VERSION "HIPBNYYYYYYYYYYYYYYYYYYYYYYYYYYYYYYYYYYYYY/4/%%%/4/'%**4YYY///"

NS_ :

BS_:

BU_: VCU DCDC

BO_ 2566834864 DcDc_DM1: 6 DCDC

BO_ 2565406640 DcDc_unknown: 8 DCDC

BO_ 2632712112 DcDc_TPDT: 8 DCDC

BO_ 2632777648 DcDc_TPCM: 8 DCDC

BO_ 2565518331 DcDc_RQST: 8 DCDC
 SG_ ParameterGroupNumber : 0|24@1+ (1,0) [0|0] "" Vector__XXX

BO_ 2565845243 VCU_DcDc_Setpoints: 8 VCU
 SG_ CMD_RemoteTurnOn m0 : 40|1@1+ (1,0) [0|1] ""  DCDC
 SG_ CMD_CoolantTempWarning_Threshold m2 : 24|16@1- (0.1,0) [40|90] "deg C"  DCDC
 SG_ CMD_CoolantTempFault_Threshold m2 : 8|16@1- (0.1,0) [50|90] "deg C"  DCDC
 SG_ CMD_OutputUnderVoltageFaultThres m1 : 8|16@1+ (0.05,0) [8|15.95] "V"  DCDC
 SG_ CMD_OutputOverVoltageFaultThresh m1 : 24|16@1+ (0.05,0) [9.05|18] "V"  DCDC
 SG_ CMD_OutputCurrentLimit m0 : 24|16@1+ (0.05,0) [200|291] "A"  DCDC
 SG_ CMD_OutputVoltageSetpoint m0 : 8|16@1+ (0.05,0) [9|16] "V"  DCDC
 SG_ index_byte M : 0|8@1+ (1,0) [0|255] ""  DCDC

BO_ 2566902960 DcDc_F_W_S_Message: 8 DCDC
 SG_ STS_Hiccup : 57|1@1+ (1,0) [0|1] ""  VCU
 SG_ STS_ReversPolarity : 56|1@1+ (1,0) [0|1] ""  VCU
 SG_ FLT_ReversPolarity : 13|1@1+ (1,0) [0|1] ""  VCU
 SG_ WAR_CurrentLimiting : 25|1@1+ (1,0) [0|1] ""  VCU
 SG_ WAR_CoolantOTP : 24|1@1+ (1,0) [0|1] ""  VCU
 SG_ STS_Wakeup : 49|1@1+ (1,0) [0|1] ""  VCU
 SG_ STS_UnitEnabled : 48|1@1+ (1,0) [0|1] ""  VCU
 SG_ STS_StartUpInitDone : 53|1@1+ (1,0) [0|1] ""  VCU
 SG_ STS_RemoteShutdown : 52|1@1+ (1,0) [0|1] ""  VCU
 SG_ STS_LatchedFault : 51|1@1+ (1,0) [0|1] ""  VCU
 SG_ STS_InputOk : 54|1@1+ (1,0) [0|1] ""  VCU
 SG_ STS_HVIL_OK : 55|1@1+ (1,0) [0|1] ""  VCU
 SG_ STS_Fault : 50|1@1+ (1,0) [0|1] ""  VCU
 SG_ FLT_ThermistorFault : 10|1@1+ (1,0) [0|1] ""  VCU
 SG_ FLT_ShortCircuit : 9|1@1+ (1,0) [0|1] ""  VCU
 SG_ FLT_OutputUV : 2|1@1+ (1,0) [0|1] ""  VCU
 SG_ FLT_OutputOV : 3|1@1+ (1,0) [0|1] ""  VCU
 SG_ FLT_OutputOC : 4|1@1+ (1,0) [0|1] ""  VCU
 SG_ FLT_OTP : 5|1@1+ (1,0) [0|1] ""  VCU
 SG_ FLT_InputUV : 0|1@1+ (1,0) [0|1] ""  VCU
 SG_ FLT_InputOV : 1|1@1+ (1,0) [0|1] ""  VCU
 SG_ FLT_I2Cfault : 6|1@1+ (1,0) [0|1] ""  VCU
 SG_ FLT_EEPROM_CRCfault : 8|1@1+ (1,0) [0|1] ""  VCU
 SG_ FLT_CANfault : 7|1@1+ (1,0) [0|1] ""  VCU
 SG_ FLT_OutputOVlatch : 12|1@1+ (1,0) [0|1] ""  VCU
 SG_ FLT_Overload : 11|1@1+ (1,0) [0|1] ""  VCU

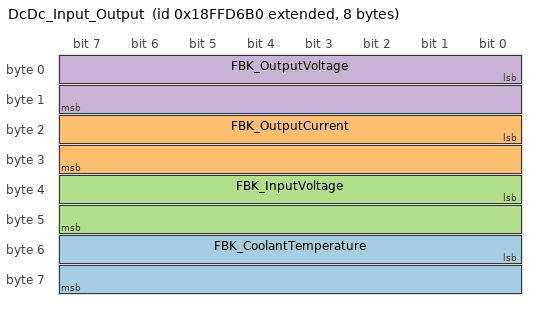
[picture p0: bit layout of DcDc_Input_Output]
BO_ 2566903472 DcDc_Input_Output: 8 DCDC
 SG_ FBK_CoolantTemperature : 48|16@1- (0.1,0) [-40|90] "deg C"  VCU
 SG_ FBK_OutputCurrent : 16|16@1+ (0.05,0) [0|3276.75] "A"  VCU
 SG_ FBK_InputVoltage : 32|16@1+ (0.05,0) [0|3276.75] "V"  VCU
 SG_ FBK_OutputVoltage : 0|16@1+ (0.05,0) [0|3276.75] "V"  VCU

CM_ SG_ 2565845243 CMD_CoolantTempWarning_Threshold "the coolant temeperature value treshold. If this temperature is exceeded then coolant warning is generated";
CM_ SG_ 2565845243 CMD_CoolantTempFault_Threshold "the coolant temeperature value treshold. If this temperature is exceeded then coolant fault is generated";
CM_ SG_ 2565845243 CMD_OutputUnderVoltageFaultThres "set the voltage value for treshold of undervoltage error. If ouput voltage falls below this value then undervoltage fault is generated by power supply.";
CM_ SG_ 2565845243 CMD_OutputOverVoltageFaultThresh "set the voltage value for treshold of overvoltage error. If output voltage exceeds this value then overvoltage fault is generated by power supply.";
CM_ SG_ 2565845243 CMD_OutputCurrentLimit "set the desired value of power supply output Current limit. Above this value the unit will drop output Voltage according current limiting curve.";
CM_ SG_ 2565845243 CMD_OutputVoltageSetpoint "set the desired value of power supply output Voltage";
BA_DEF_ SG_  "SigType" ENUM  "Default","Range","RangeSigned","ASCII","Discrete","Control","ReferencePGN","DTC","StringDelimiter","StringLength","StringLengthControl";
BA_DEF_ SG_  "GenSigEVName" STRING ;
BA_DEF_ SG_  "GenSigILSupport" ENUM  "No","Yes";
BA_DEF_ SG_  "GenSigSendType" ENUM  "Cyclic","OnWrite","OnWriteWithRepetition","OnChange","OnChangeWithRepetition","IfActive","IfActiveWithRepetition","NoSigSendType";
BA_DEF_ SG_  "GenSigStartValue" INT 0 10000;
BA_DEF_ BO_  "GenMsgILSupport" ENUM  "No","Yes";
BA_DEF_ BO_  "GenMsgStartDelayTime" INT 0 100000;
BA_DEF_ BU_  "NmStationAddress" INT 0 255;
BA_DEF_ BO_  "GenMsgSendType" ENUM  "cyclic","NotUsed","IfActive","NotUsed","NotUsed","NotUsed","NotUsed","NotUsed","noMsgSendType";
BA_DEF_ BO_  "GenMsgRequestable" INT 0 1;
BA_DEF_ BO_  "GenMsgCycleTime" INT 0 3600000;
BA_DEF_  "DBName" STRING ;
BA_DEF_  "BusType" STRING ;
BA_DEF_ SG_  "SystemSignalLongSymbol" STRING ;
BA_DEF_DEF_  "SigType" "Default";
BA_DEF_DEF_  "GenSigEVName" "Env@Nodename_@Signame";
BA_DEF_DEF_  "GenSigILSupport" "Yes";
BA_DEF_DEF_  "GenSigSendType" "NoSigSendType";
BA_DEF_DEF_  "GenSigStartValue" 0;
BA_DEF_DEF_  "GenMsgILSupport" "Yes";
BA_DEF_DEF_  "GenMsgStartDelayTime" 0;
BA_DEF_DEF_  "NmStationAddress" 254;
BA_DEF_DEF_  "GenMsgSendType" "noMsgSendType";
BA_DEF_DEF_  "GenMsgRequestable" 1;
BA_DEF_DEF_  "GenMsgCycleTime" 0;
BA_DEF_DEF_  "DBName" "";
BA_DEF_DEF_  "BusType" "CAN";
BA_DEF_DEF_  "SystemSignalLongSymbol" "";
BA_ "DBName" "Node_DCDC";
BA_ "NmStationAddress" BU_ VCU 97;
BA_ "NmStationAddress" BU_ DCDC 176;
BA_ "GenMsgCycleTime" BO_ 2566834864 1000;
BA_ "GenMsgSendType" BO_ 2566834864 0;
BA_ "GenMsgSendType" BO_ 2565406640 0;
BA_ "GenMsgCycleTime" BO_ 2565406640 100;
BA_ "GenMsgSendType" BO_ 2632712112 2;
BA_ "GenMsgSendType" BO_ 2632777648 2;
BA_ "GenMsgSendType" BO_ 2565518331 2;
BA_ "GenMsgCycleTime" BO_ 2565845243 100;
BA_ "GenMsgSendType" BO_ 2565845243 0;
BA_ "GenMsgCycleTime" BO_ 2566902960 100;
BA_ "GenMsgCycleTime" BO_ 2566903472 100;
BA_ "GenSigStartValue" SG_ 2565845243 CMD_CoolantTempWarning_Threshold 800;
BA_ "GenSigStartValue" SG_ 2565845243 CMD_CoolantTempFault_Threshold 900;
BA_ "GenSigStartValue" SG_ 2565845243 CMD_OutputUnderVoltageFaultThres 160;
BA_ "SystemSignalLongSymbol" SG_ 2565845243 CMD_OutputUnderVoltageFaultThres "CMD_OutputUnderVoltageFaultThreshold";
BA_ "GenSigStartValue" SG_ 2565845243 CMD_OutputOverVoltageFaultThresh 340;
BA_ "SystemSignalLongSymbol" SG_ 2565845243 CMD_OutputOverVoltageFaultThresh "CMD_OutputOverVoltageFaultThreshold";
BA_ "GenSigStartValue" SG_ 2565845243 CMD_OutputCurrentLimit 5820;
BA_ "GenSigStartValue" SG_ 2565845243 CMD_OutputVoltageSetpoint 288;
VAL_ 2565845243 CMD_RemoteTurnOn 1 "Turn ON oputput" 0 "Turn OFF output" ;
VAL_ 2566902960 STS_Hiccup 0 "no Hiccup" 1 "Hiccup" ;
VAL_ 2566902960 STS_ReversPolarity 0 "no ReversPolarity" 1 "ReversPolarity" ;
VAL_ 2566902960 FLT_ReversPolarity 0 "no ReversPolarity" 1 "ReversPolarity" ;
VAL_ 2566902960 WAR_CurrentLimiting 0 "no warning CurrentLimiting" 1 "warning CurrentLimiting" ;
VAL_ 2566902960 WAR_CoolantOTP 0 "no warningCoolantOTP" 1 "warningCoolantOTP" ;
VAL_ 2566902960 STS_Wakeup 0 "no Wakeup" 1 "Wakeup" ;
VAL_ 2566902960 STS_UnitEnabled 0 "not UnitEnabled" 1 "UnitEnabled" ;
VAL_ 2566902960 STS_StartUpInitDone 0 "not StartUpInitDone" 1 "StartUpInitDone" ;
VAL_ 2566902960 STS_RemoteShutdown 1 "Turn OFF oputput" 0 "Turn ON output" ;
VAL_ 2566902960 STS_LatchedFault 0 "no LatchedFault" 1 "LatchedFault" ;
VAL_ 2566902960 STS_InputOk 0 "no InputOk" 1 "InputOk" ;
VAL_ 2566902960 STS_HVIL_OK 0 "no HVIL OK" 1 "HVIL OK" ;
VAL_ 2566902960 STS_Fault 0 "no Fault" 1 "Fault" ;
VAL_ 2566902960 FLT_ThermistorFault 0 "no ThermistorFault" 1 "ThermistorFault" ;
VAL_ 2566902960 FLT_ShortCircuit 0 "no ShortCircuit" 1 "ShortCircuit" ;
VAL_ 2566902960 FLT_OutputUV 0 "no OutputUV" 1 "OutputUV" ;
VAL_ 2566902960 FLT_OutputOV 0 "no Output OV" 1 "OutputOV" ;
VAL_ 2566902960 FLT_OutputOC 0 "no Over Current" 1 "Over Current" ;
VAL_ 2566902960 FLT_OTP 0 "no Over Temperature Protection" 1 "Over Temperature Protection" ;
VAL_ 2566902960 FLT_InputUV 0 "no inputUV" 1 "inputUV" ;
VAL_ 2566902960 FLT_InputOV 0 "no inputOV" 1 "inputOV" ;
VAL_ 2566902960 FLT_I2Cfault 0 "no I2C fault" 1 "I2C fault" ;
VAL_ 2566902960 FLT_EEPROM_CRCfault 0 "no CRC fault" 1 "CRC fault" ;
VAL_ 2566902960 FLT_CANfault 0 "no CAN fault" 1 "CAN fault" ;
VAL_ 2566902960 FLT_OutputOVlatch 0 "no OutputOVlatch" 1 "OutputOVlatch" ;
VAL_ 2566902960 FLT_Overload 0 "no Overload" 1 "Overload" ;
